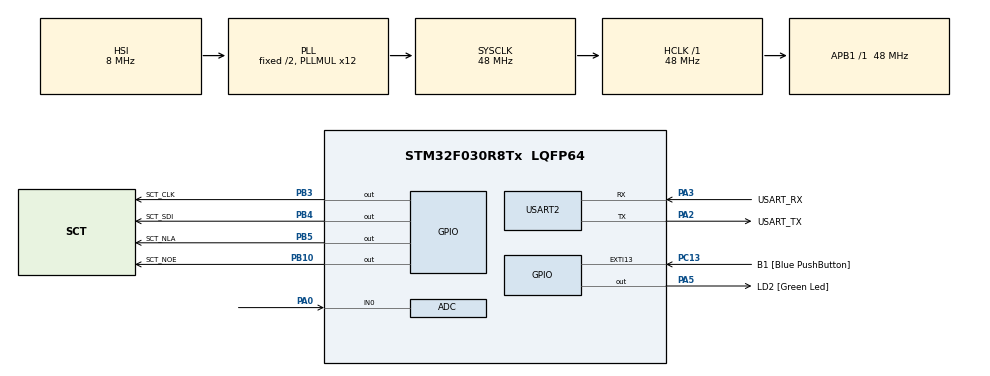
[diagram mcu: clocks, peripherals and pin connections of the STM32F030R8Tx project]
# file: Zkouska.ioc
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ADC.ClockPrescaler=ADC_CLOCK_SYNC_PCLK_DIV4
ADC.ContinuousConvMode=ENABLE
ADC.SamplingTime=ADC_SAMPLETIME_239CYCLES_5
Mcu.Family=STM32F0
Mcu.Name=STM32F030R8Tx
Mcu.Package=LQFP64
NVIC.TIM17_IRQn=true\:0\:0\:false\:false\:true\:true\:true\:true
PA0.Mode=IN0
PA0.Signal=ADC_IN0
PA13.GPIO_Label=TMS
PA13.Mode=Serial_Wire
PA13.Signal=SYS_SWDIO
PA14.GPIO_Label=TCK
PA14.Mode=Serial_Wire
PA14.Signal=SYS_SWCLK
PA2.GPIO_Label=USART_TX
PA2.GPIO_Mode=GPIO_MODE_AF_PP
PA2.GPIO_PuPd=GPIO_NOPULL
PA2.GPIO_Speed=GPIO_SPEED_FREQ_LOW
PA2.Mode=Asynchronous
PA2.Signal=USART2_TX
PA3.GPIO_Label=USART_RX
PA3.GPIO_Mode=GPIO_MODE_AF_PP
PA3.GPIO_PuPd=GPIO_NOPULL
PA3.GPIO_Speed=GPIO_SPEED_FREQ_LOW
PA3.Mode=Asynchronous
PA3.Signal=USART2_RX
PA5.GPIO_Label=LD2 [Green Led]
PA5.GPIO_Mode=GPIO_MODE_OUTPUT_PP
PA5.GPIO_PuPd=GPIO_NOPULL
PA5.GPIO_Speed=GPIO_SPEED_FREQ_LOW
PA5.Signal=GPIO_Output
PB10.GPIO_Label=SCT_NOE
PB10.Signal=GPIO_Output
PB3.GPIO_Label=SCT_CLK
PB3.Signal=GPIO_Output
PB4.GPIO_Label=SCT_SDI
PB4.Signal=GPIO_Output
PB5.GPIO_Label=SCT_NLA
PB5.Signal=GPIO_Output
PC13.GPIO_Label=B1 [Blue PushButton]
PC13.GPIO_ModeDefaultEXTI=GPIO_MODE_IT_FALLING
PC13.Signal=GPXTI13
PC14-OSC32_IN.Mode=LSE-External-Oscillator
PC14-OSC32_IN.Signal=RCC_OSC32_IN
PC15-OSC32_OUT.Mode=LSE-External-Oscillator
PC15-OSC32_OUT.Signal=RCC_OSC32_OUT
PF0-OSC_IN.Mode=HSE-External-Clock-Source
PF0-OSC_IN.Signal=RCC_OSC_IN
PF1-OSC_OUT.Signal=RCC_OSC_OUT
ProjectManager.HeapSize=0x200
ProjectManager.StackSize=0x400
ProjectManager.TargetToolchain=STM32CubeIDE
RCC.AHBFreq_Value=48000000
RCC.APB1Freq_Value=48000000
RCC.APB1TimFreq_Value=48000000
RCC.HCLKFreq_Value=48000000
RCC.PLLMUL=RCC_PLL_MUL12
RCC.SYSCLKFreq_VALUE=48000000
RCC.SYSCLKSource=RCC_SYSCLKSOURCE_PLLCLK
TIM17.Prescaler=8
USART2.VirtualMode-Asynchronous=VM_ASYNC
VP_TIM17_VS_ClockSourceINT.Mode=Enable_Timer
board=NUCLEO-F030R8

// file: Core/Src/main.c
/* USER CODE BEGIN Header */
/**
  ******************************************************************************
  * @file           : main.c
  * @brief          : Main program body
  ******************************************************************************
  * @attention
  *
  * Copyright (c) 2024 STMicroelectronics.
  * All rights reserved.
  *
  * This software is licensed under terms that can be found in the LICENSE file
  * in the root directory of this software component.
  * If no LICENSE file comes with this software, it is provided AS-IS.
  *
  ******************************************************************************
  */
/* USER CODE END Header */
#include "main.h"
#include "adc.h"
#include "tim.h"
#include "usart.h"
#include "gpio.h"

/* USER CODE BEGIN Includes */
#include "sct.h"
#include "adc.h"
#include "tim.h"
#include "chaser.h"
/* USER CODE END Includes */

void SystemClock_Config(void);

int main(void)
{

  /* MCU Configuration--------------------------------------------------------*/

  /* Reset of all peripherals, Initializes the Flash interface and the Systick. */
  HAL_Init();

  /* Configure the system clock */
  SystemClock_Config();

  /* Initialize all configured peripherals */
  MX_GPIO_Init();
  MX_USART2_UART_Init();
  MX_ADC_Init();
  MX_TIM17_Init();
  /* USER CODE BEGIN 2 */
  //adc startup
  HAL_ADCEx_Calibration_Start(&hadc);
  HAL_ADC_Start(&hadc);
  //timer interrupt startup
  HAL_TIM_Base_Start_IT(&htim17);

  sct_init();
  initChaserADC();

  /* USER CODE END 2 */

  /* Infinite loop */
  /* USER CODE BEGIN WHILE */
  while (1)
  {
	handleChaser();
    /* USER CODE END WHILE */

  }
}

void SystemClock_Config(void)
{
  RCC_OscInitTypeDef RCC_OscInitStruct = {0};
  RCC_ClkInitTypeDef RCC_ClkInitStruct = {0};

  /** Initializes the RCC Oscillators according to the specified parameters
  * in the RCC_OscInitTypeDef structure.
  */
  RCC_OscInitStruct.OscillatorType = RCC_OSCILLATORTYPE_HSI;
  RCC_OscInitStruct.HSIState = RCC_HSI_ON;
  RCC_OscInitStruct.HSICalibrationValue = RCC_HSICALIBRATION_DEFAULT;
  RCC_OscInitStruct.PLL.PLLState = RCC_PLL_ON;
  RCC_OscInitStruct.PLL.PLLSource = RCC_PLLSOURCE_HSI;
  RCC_OscInitStruct.PLL.PLLMUL = RCC_PLL_MUL12;
  RCC_OscInitStruct.PLL.PREDIV = RCC_PREDIV_DIV1;
  if (HAL_RCC_OscConfig(&RCC_OscInitStruct) != HAL_OK)
  {
    Error_Handler();
  }

  /** Initializes the CPU, AHB and APB buses clocks
  */
  RCC_ClkInitStruct.ClockType = RCC_CLOCKTYPE_HCLK|RCC_CLOCKTYPE_SYSCLK
                              |RCC_CLOCKTYPE_PCLK1;
  RCC_ClkInitStruct.SYSCLKSource = RCC_SYSCLKSOURCE_PLLCLK;
  RCC_ClkInitStruct.AHBCLKDivider = RCC_SYSCLK_DIV1;
  RCC_ClkInitStruct.APB1CLKDivider = RCC_HCLK_DIV1;

  if (HAL_RCC_ClockConfig(&RCC_ClkInitStruct, FLASH_LATENCY_1) != HAL_OK)
  {
    Error_Handler();
  }
}

void Error_Handler(void)
{
  __disable_irq();
  while (1)
  {
  }
}
